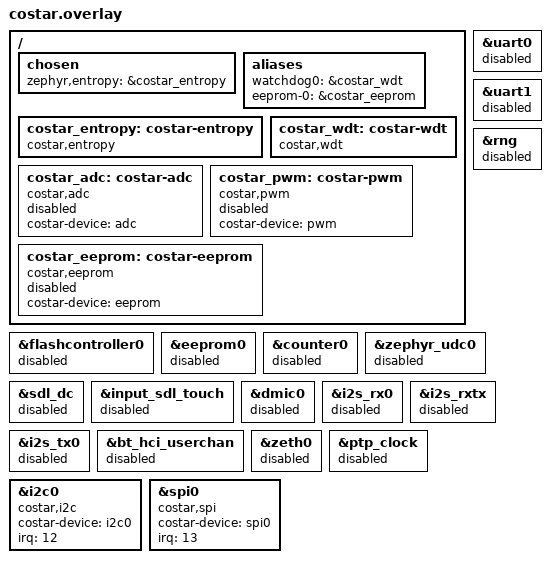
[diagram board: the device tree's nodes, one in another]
/*
 * The costar shield, applied to every costar Zephyr image.
 *
 * native_sim devices whose host side lives in Zephyr's own runner (PTY
 * UARTs, file-backed flash and EEPROM, host RNG and counter, audio, SDL,
 * USB, Bluetooth user channel, TAP) are disabled.  costar provides devices
 * of its own instead (costar,uart, costar,flash); applications declare them,
 * and may point chosen nodes at them, in their own overlay, which is applied
 * after this one.  The host RNG's replacement, deterministic costar,entropy,
 * is declared here and is zephyr,entropy.  So are a costar,wdt watchdog
 * (alias watchdog0), on the scenario's device named wdt, and an ADC, a PWM
 * controller and an EEPROM (the eeprom-0 alias), on devices named adc, pwm
 * and eeprom, disabled until an application enables them
 * (&costar_adc { status = "okay"; }).  native_sim's I2C controller, i2c0,
 * becomes a costar,i2c controller on the channel "i2c0" (IRQ 12), and its
 * SPI controller, spi0, a costar,spi one on the channel "spi0" (IRQ 13), so
 * applications put their parts on &i2c0 and &spi0 as on a real board.
 * Other pure software emulators (gpio/adc/rtc emul, CAN loopback) stay
 * available; an overlay can make i2c0 or spi0 an emulator again.
 */
/ {
	chosen {
		/delete-property/ zephyr,console;
		/delete-property/ zephyr,shell-uart;
		/delete-property/ zephyr,uart-mcumgr;
		/delete-property/ zephyr,flash;
		/delete-property/ zephyr,flash-controller;
		/delete-property/ zephyr,code-partition;
		zephyr,entropy = &costar_entropy;
		/delete-property/ zephyr,display;
		/delete-property/ zephyr,touch;
		/delete-property/ zephyr,bt-hci;
	};

	aliases {
		watchdog0 = &costar_wdt;
		eeprom-0 = &costar_eeprom;
	};

	costar_entropy: costar-entropy {
		compatible = "costar,entropy";
	};

	costar_wdt: costar-wdt {
		compatible = "costar,wdt";
	};

	costar_adc: costar-adc {
		compatible = "costar,adc";
		costar-device = "adc";
		#io-channel-cells = <1>;
		#address-cells = <1>;
		#size-cells = <0>;
		status = "disabled";
	};

	costar_pwm: costar-pwm {
		compatible = "costar,pwm";
		costar-device = "pwm";
		#pwm-cells = <3>;
		status = "disabled";
	};

	costar_eeprom: costar-eeprom {
		compatible = "costar,eeprom";
		costar-device = "eeprom";
		status = "disabled";
	};
};

&uart0 { status = "disabled"; };
&uart1 { status = "disabled"; };
&flashcontroller0 { status = "disabled"; };
&eeprom0 { status = "disabled"; };
&rng { status = "disabled"; };
&counter0 { status = "disabled"; };
&zephyr_udc0 { status = "disabled"; };
&sdl_dc { status = "disabled"; };
&input_sdl_touch { status = "disabled"; };
&dmic0 { status = "disabled"; };
&i2s_rx0 { status = "disabled"; };
&i2s_rxtx { status = "disabled"; };
&i2s_tx0 { status = "disabled"; };
&bt_hci_userchan { status = "disabled"; };
&zeth0 { status = "disabled"; };
&ptp_clock { status = "disabled"; };

&i2c0 {
	compatible = "costar,i2c";
	costar-device = "i2c0";
	irq = <12>;
	/delete-property/ #forward-cells;
};

&spi0 {
	compatible = "costar,spi";
	costar-device = "spi0";
	irq = <13>;
};
